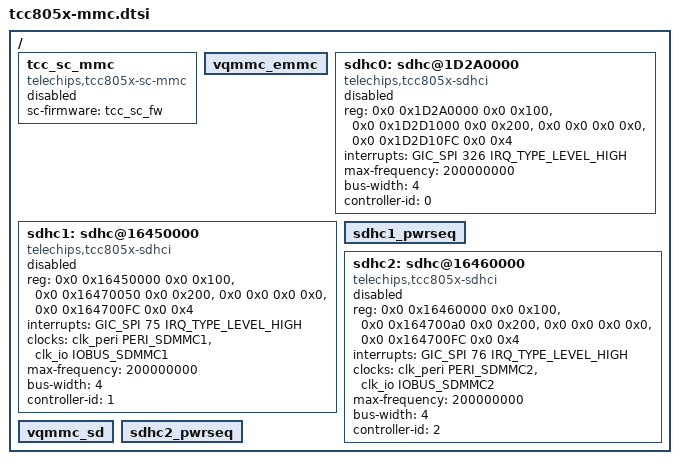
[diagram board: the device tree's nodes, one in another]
// SPDX-License-Identifier: (GPL-2.0-or-later OR MIT)
/*
 * Copyright (C) 2023 Telechips Inc.
 */

#include <dt-bindings/clock/telechips,tcc805x-clks.h>
#include <dt-bindings/interrupt-controller/arm-gic.h>

/ {
	tcc_sc_mmc: tcc_sc_mmc {
		compatible = "telechips,tcc805x-sc-mmc";
		status = "disabled";
		sc-firmware = <&tcc_sc_fw>;
	};

	vqmmc_emmc: vqmmc_emmc {};

	sdhc0: sdhc@1D2A0000 {
		compatible = "telechips,tcc805x-sdhci";
		reg = <0x0 0x1D2A0000 0x0 0x100>,
		      <0x0 0x1D2D1000 0x0 0x200>,
		      <0x0 0x0 0x0 0x0> /* dummy */,
		      <0x0 0x1D2D10FC 0x0 0x4>;
		interrupts = <GIC_SPI 326 IRQ_TYPE_LEVEL_HIGH>;
		max-frequency = <200000000>;
		bus-width = <4>;
		controller-id = <0>;
		status = "disabled";
	};

	sdhc1: sdhc@16450000 {
		compatible = "telechips,tcc805x-sdhci";
		reg = <0x0 0x16450000 0x0 0x100>,
		      <0x0 0x16470050 0x0 0x200>,
		      <0x0 0x0 0x0 0x0> /* dummy */,
		      <0x0 0x164700FC 0x0 0x4>;
		interrupts = <GIC_SPI 75 IRQ_TYPE_LEVEL_HIGH>;
		clocks = <&clk_peri PERI_SDMMC1 &clk_io IOBUS_SDMMC1>;
		clock-names = "mmc_fclk", "mmc_hclk";
		max-frequency = <200000000>;
		bus-width = <4>;
		controller-id = <1>;
		status = "disabled";
	};

	sdhc1_pwrseq: sdhc1_pwrseq {};

	sdhc2: sdhc@16460000 {
		compatible = "telechips,tcc805x-sdhci";
		reg = <0x0 0x16460000 0x0 0x100>,
		      <0x0 0x164700a0 0x0 0x200>,
		      <0x0 0x0 0x0 0x0> /* dummy */,
		      <0x0 0x164700FC 0x0 0x4>;
		interrupts = <GIC_SPI 76 IRQ_TYPE_LEVEL_HIGH>;
		clocks = <&clk_peri PERI_SDMMC2 &clk_io IOBUS_SDMMC2>;
		clock-names = "mmc_fclk", "mmc_hclk";
		max-frequency = <200000000>;
		bus-width = <4>;
		controller-id = <2>;
		status = "disabled";
	};

	vqmmc_sd: vqmmc_sd {};
	sdhc2_pwrseq: sdhc2_pwrseq {};
};
